# MKV44F15 register map
Vendor: Freescale Semiconductor, Inc.; Series: Kinetis_V; File version: 1.6
CPU: CM4 r0p1, little endian, no MPU, FPU, VTOR, 4 interrupt priority bits
Registers are 32-bit, read-write, reset 0x0 unless marked. A register's access mark holds for its fields unless they carry their own. Offsets are from the block's base; [hi:lo] are bit positions; {n}, {i} and the like mark numbered series.

## WDOG — Generation 2008 Watchdog Timer
Base 0x40052000; register names take the prefix WDOG_
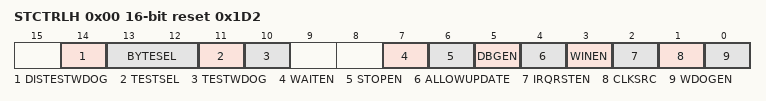
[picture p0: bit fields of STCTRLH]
0x00 STCTRLH 16-bit reset 0x1D2 — Watchdog Status and Control Register High
  [14] DISTESTWDOG
    0=WDOG functional test mode is not disabled; 1=WDOG functional test mode is disabled permanently until reset
  [13:12] BYTESEL
    {v}=Byte {v} selected (v=0..3)
  [11] TESTSEL
    0=Quick test. The timer runs in normal operation. You can load a small time-out value to do a quick test.; 1=Byte test. Puts the timer in the byte test mode where individual bytes of the timer are enabled for operation and are compared for time-out against the corresponding byte of the programmed time-out value. Select the byte through BYTESEL[1:0] for testing.
  [10] TESTWDOG
  [7] WAITEN
    0=WDOG is disabled in CPU Wait mode; 1=WDOG is enabled in CPU Wait mode
  [6] STOPEN
    0=WDOG is disabled in CPU Stop mode; 1=WDOG is enabled in CPU Stop mode
  [5] DBGEN
    0=WDOG is disabled in CPU Debug mode; 1=WDOG is enabled in CPU Debug mode
  [4] ALLOWUPDATE
    0=No further updates allowed to WDOG write-once registers; 1=WDOG write-once registers can be unlocked for updating
  [3] WINEN
    0=Windowing mode is disabled; 1=Windowing mode is enabled
  [2] IRQRSTEN
    0=WDOG time-out generates reset only; 1=WDOG time-out initially generates an interrupt. After WCT, it generates a reset.
  [1] CLKSRC
    0=WDOG clock sourced from LPO ; 1=WDOG clock sourced from alternate clock source
  [0] WDOGEN
    0=WDOG is disabled; 1=WDOG is enabled
0x02 STCTRLL 16-bit reset 0x1 — Watchdog Status and Control Register Low
  [15] INTFLG
0x04 TOVALH 16-bit reset 0x4C — Watchdog Time-out Value Register High
  [15:0] TOVALHIGH
0x06 TOVALL 16-bit reset 0x4B4C — Watchdog Time-out Value Register Low
  [15:0] TOVALLOW
0x08 WINH 16-bit — Watchdog Window Register High
  [15:0] WINHIGH
0x0A WINL 16-bit reset 0x10 — Watchdog Window Register Low
  [15:0] WINLOW
0x0C REFRESH 16-bit reset 0xB480 — Watchdog Refresh register
  [15:0] WDOGREFRESH
0x0E UNLOCK 16-bit reset 0xD928 — Watchdog Unlock register
  [15:0] WDOGUNLOCK
0x10 TMROUTH 16-bit — Watchdog Timer Output Register High
  [15:0] TIMEROUTHIGH
0x12 TMROUTL 16-bit — Watchdog Timer Output Register Low
  [15:0] TIMEROUTLOW
0x14 RSTCNT 16-bit — Watchdog Reset Count register
0x16 PRESC 16-bit reset 0x400 — Watchdog Prescaler register
  [10:8] PRESCVAL

## XBARA — Crossbar Switch
Base 0x40059000; register names take the prefix XBARA_
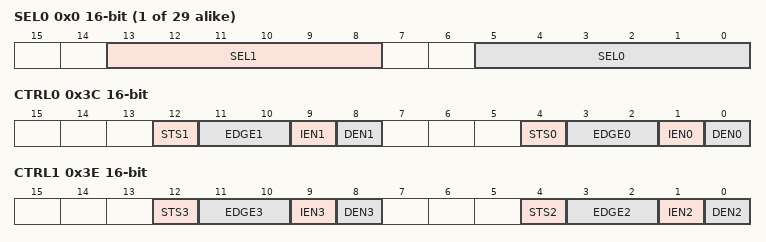
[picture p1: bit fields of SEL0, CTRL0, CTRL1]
{0x0+2i} SEL{i} 16-bit (i=0..28) — Crossbar A Select Register {i}
  [13:8] SEL{2i+1}, [5:0] SEL{2i}
0x3A SEL29 16-bit — Crossbar A Select Register 29
  [5:0] SEL58
0x3C CTRL0 16-bit — Crossbar A Control Register 0
  [12] STS1 — Edge detection status for XBAR_OUT1
    0=Active edge not yet detected on XBAR_OUT1; 1=Active edge detected on XBAR_OUT1
  [11:10] EDGE1 — Active edge for edge detection on XBAR_OUT1
    0=STS1 never asserts; 1=STS1 asserts on rising edges of XBAR_OUT1; 2=STS1 asserts on falling edges of XBAR_OUT1; 3=STS1 asserts on rising and falling edges of XBAR_OUT1
  [9] IEN1 — Interrupt Enable for XBAR_OUT1
    0=Interrupt disabled; 1=Interrupt enabled
  [8] DEN1 — DMA Enable for XBAR_OUT1
    0=DMA disabled; 1=DMA enabled
  [4] STS0 — Edge detection status for XBAR_OUT0
    0=Active edge not yet detected on XBAR_OUT0; 1=Active edge detected on XBAR_OUT0
  [3:2] EDGE0 — Active edge for edge detection on XBAR_OUT0
    0=STS0 never asserts; 1=STS0 asserts on rising edges of XBAR_OUT0; 2=STS0 asserts on falling edges of XBAR_OUT0; 3=STS0 asserts on rising and falling edges of XBAR_OUT0
  [1] IEN0 — Interrupt Enable for XBAR_OUT0
    0=Interrupt disabled; 1=Interrupt enabled
  [0] DEN0 — DMA Enable for XBAR_OUT0
    0=DMA disabled; 1=DMA enabled
0x3E CTRL1 16-bit — Crossbar A Control Register 1
  [12] STS3 — Edge detection status for XBAR_OUT3
    0=Active edge not yet detected on XBAR_OUT3; 1=Active edge detected on XBAR_OUT3
  [11:10] EDGE3 — Active edge for edge detection on XBAR_OUT3
    0=STS3 never asserts; 1=STS3 asserts on rising edges of XBAR_OUT3; 2=STS3 asserts on falling edges of XBAR_OUT3; 3=STS3 asserts on rising and falling edges of XBAR_OUT3
  [9] IEN3 — Interrupt Enable for XBAR_OUT3
    0=Interrupt disabled; 1=Interrupt enabled
  [8] DEN3 — DMA Enable for XBAR_OUT3
    0=DMA disabled; 1=DMA enabled
  [4] STS2 — Edge detection status for XBAR_OUT2
    0=Active edge not yet detected on XBAR_OUT2; 1=Active edge detected on XBAR_OUT2
  [3:2] EDGE2 — Active edge for edge detection on XBAR_OUT2
    0=STS2 never asserts; 1=STS2 asserts on rising edges of XBAR_OUT2; 2=STS2 asserts on falling edges of XBAR_OUT2; 3=STS2 asserts on rising and falling edges of XBAR_OUT2
  [1] IEN2 — Interrupt Enable for XBAR_OUT2
    0=Interrupt disabled; 1=Interrupt enabled
  [0] DEN2 — DMA Enable for XBAR_OUT2
    0=DMA disabled; 1=DMA enabled

## Notices in the file
Redistribution and use in source and binary forms, with or without modification,
are permitted provided that the following conditions are met:
o Redistributions of source code must retain the above copyright notice, this list
of conditions and the following disclaimer.
o Redistributions in binary form must reproduce the above copyright notice, this
list of conditions and the following disclaimer in the documentation and/or
other materials provided with the distribution.
o Neither the name of Freescale Semiconductor, Inc. nor the names of its
contributors may be used to endorse or promote products derived from this
software without specific prior written permission.
THIS SOFTWARE IS PROVIDED BY THE COPYRIGHT HOLDERS AND CONTRIBUTORS "AS IS" AND
ANY EXPRESS OR IMPLIED WARRANTIES, INCLUDING, BUT NOT LIMITED TO, THE IMPLIED
WARRANTIES OF MERCHANTABILITY AND FITNESS FOR A PARTICULAR PURPOSE ARE
DISCLAIMED. IN NO EVENT SHALL THE COPYRIGHT HOLDER OR CONTRIBUTORS BE LIABLE FOR
ANY DIRECT, INDIRECT, INCIDENTAL, SPECIAL, EXEMPLARY, OR CONSEQUENTIAL DAMAGES
(INCLUDING, BUT NOT LIMITED TO, PROCUREMENT OF SUBSTITUTE GOODS OR SERVICES;
LOSS OF USE, DATA, OR PROFITS; OR BUSINESS INTERRUPTION) HOWEVER CAUSED AND ON
ANY THEORY OF LIABILITY, WHETHER IN CONTRACT, STRICT LIABILITY, OR TORT
(INCLUDING NEGLIGENCE OR OTHERWISE) ARISING IN ANY WAY OUT OF THE USE OF THIS
SOFTWARE, EVEN IF ADVISED OF THE POSSIBILITY OF SUCH DAMAGE.
